VERSION "MFE24 Sensor Master v3 (ascii-safe)"

NS_ :

BS_:

BU_: FrontNode RearCAN RideHeight VehicleController AccelNode

BO_ 800 BrakeRotorTemps: 8 FrontNode
 SG_ BrakeTemp_FL : 0|16@1+ (0.1,0) [0|150] "degC" Vector__XXX
 SG_ BrakeTemp_FR : 16|16@1+ (0.1,0) [0|150] "degC" Vector__XXX

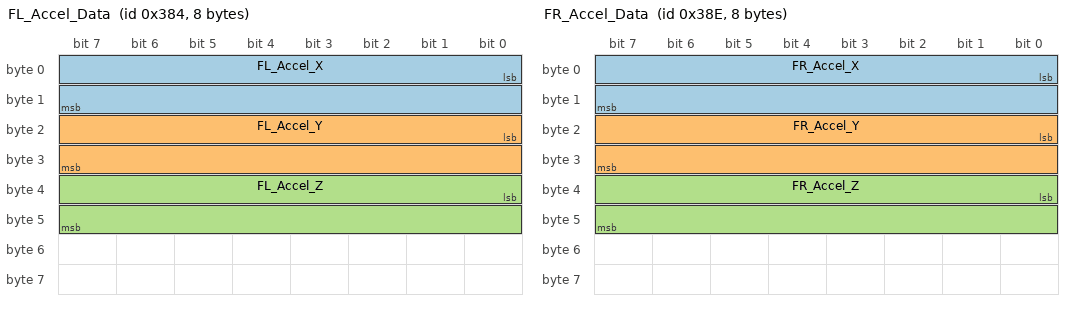
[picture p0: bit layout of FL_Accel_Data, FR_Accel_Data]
BO_ 900 FL_Accel_Data: 8 AccelNode
 SG_ FL_Accel_X : 0|16@1- (0.000244140625,0) [-524288|524287.999755859] "g" Vector__XXX
 SG_ FL_Accel_Y : 16|16@1- (0.000244140625,0) [-8|8] "g" Vector__XXX
 SG_ FL_Accel_Z : 32|16@1- (0.000244140625,0) [-8|8] "g" Vector__XXX

BO_ 910 FR_Accel_Data: 8 AccelNode
 SG_ FR_Accel_X : 0|16@1- (0.000244140625,0) [-8|8] "g" Vector__XXX
 SG_ FR_Accel_Y : 16|16@1- (0.000244140625,0) [-8|8] "g" Vector__XXX
 SG_ FR_Accel_Z : 32|16@1- (0.000244140625,0) [-8|8] "g" Vector__XXX

BO_ 700 OilTemps: 8 FrontNode
 SG_ OilTemp_Engine : 0|12@1+ (0.1,-40) [-40|170] "degC" Vector__XXX
 SG_ OilTemp_Gearbox : 12|12@1+ (0.1,-40) [-40|170] "degC" Vector__XXX

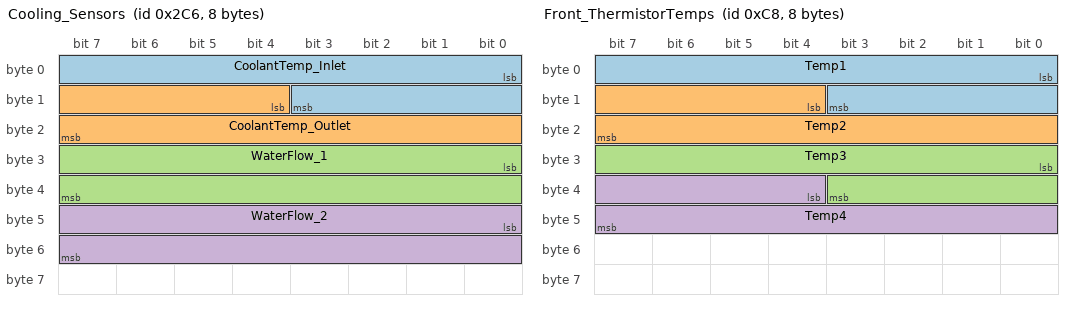
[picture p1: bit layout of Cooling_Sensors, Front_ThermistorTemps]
BO_ 710 Cooling_Sensors: 8 VehicleController
 SG_ CoolantTemp_Inlet : 0|12@1+ (0.1,-40) [-40|180] "degC" Vector__XXX
 SG_ CoolantTemp_Outlet : 12|12@1+ (0.1,-40) [-40|180] "degC" Vector__XXX
 SG_ WaterFlow_1 : 24|16@1+ (0.01,0) [0|25] "L/min" Vector__XXX
 SG_ WaterFlow_2 : 40|16@1+ (0.01,0) [0|25] "L/min" Vector__XXX

BO_ 100 FUTEK1_Load: 8 FrontNode
 SG_ Load1 : 0|16@1+ (0.1,0) [0|10000] "N" Vector__XXX

BO_ 110 FUTEK2_Load: 8 FrontNode
 SG_ Load2 : 0|16@1+ (0.1,0) [0|10000] "N" Vector__XXX

BO_ 200 Front_ThermistorTemps: 8 FrontNode
 SG_ Temp1 : 0|12@1+ (0.1,-40) [-40|180] "degC" Vector__XXX
 SG_ Temp2 : 12|12@1+ (0.1,-40) [-40|180] "degC" Vector__XXX
 SG_ Temp3 : 24|12@1+ (0.1,-40) [-40|180] "degC" Vector__XXX
 SG_ Temp4 : 36|12@1+ (0.1,-40) [-40|180] "degC" Vector__XXX

BO_ 300 Front_RotPotAngles: 8 FrontNode
 SG_ Angle1 : 0|16@1+ (0.01,0) [0|90] "deg" Vector__XXX
 SG_ Angle2 : 16|16@1+ (0.01,0) [0|90] "deg" Vector__XXX

BO_ 210 BrakeLineTemp_Front: 8 FrontNode
 SG_ BrakeLineTemp_Front : 0|16@1+ (0.1,-40) [-40|500] "degC" Vector__XXX

BO_ 400 Rear_LoadCells: 8 RearCAN
 SG_ Load1 : 0|16@1+ (0.1,0) [0|10000] "N" Vector__XXX
 SG_ Load2 : 16|16@1+ (0.1,0) [0|10000] "N" Vector__XXX

BO_ 500 Rear_RotPotAngles: 8 RearCAN
 SG_ Angle1 : 0|16@1+ (0.01,0) [0|90] "deg" Vector__XXX
 SG_ Angle2 : 16|16@1+ (0.01,0) [0|90] "deg" Vector__XXX

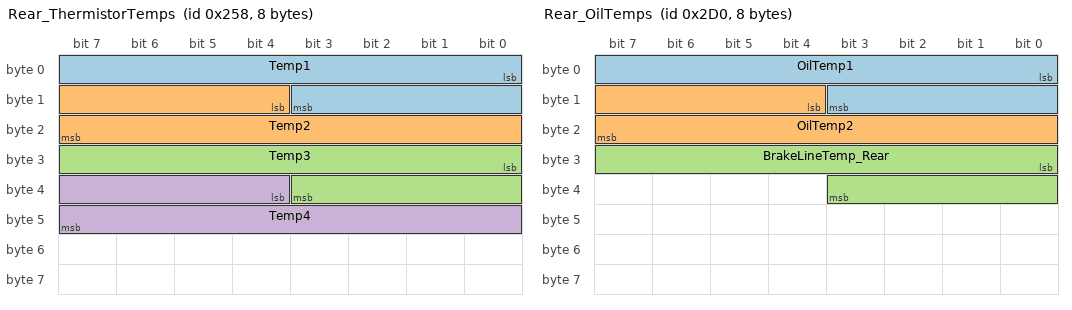
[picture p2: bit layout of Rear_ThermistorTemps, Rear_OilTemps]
BO_ 600 Rear_ThermistorTemps: 8 RearCAN
 SG_ Temp1 : 0|12@1+ (0.1,-40) [-40|180] "degC" Vector__XXX
 SG_ Temp2 : 12|12@1+ (0.1,-40) [-40|180] "degC" Vector__XXX
 SG_ Temp3 : 24|12@1+ (0.1,-40) [-40|180] "degC" Vector__XXX
 SG_ Temp4 : 36|12@1+ (0.1,-40) [-40|180] "degC" Vector__XXX

BO_ 720 Rear_OilTemps: 8 RearCAN
 SG_ OilTemp1 : 0|12@1+ (0.1,-40) [-40|170] "degC" Vector__XXX
 SG_ OilTemp2 : 12|12@1+ (0.1,-40) [-40|170] "degC" Vector__XXX
 SG_ BrakeLineTemp_Rear : 24|12@1+ (0.1,-40) [-40|500] "degC" Vector__XXX

BO_ 810 Rear_BrakeRotorTemp: 8 RearCAN
 SG_ BrakeTemp : 0|16@1+ (0.1,0) [0|150] "degC" Vector__XXX

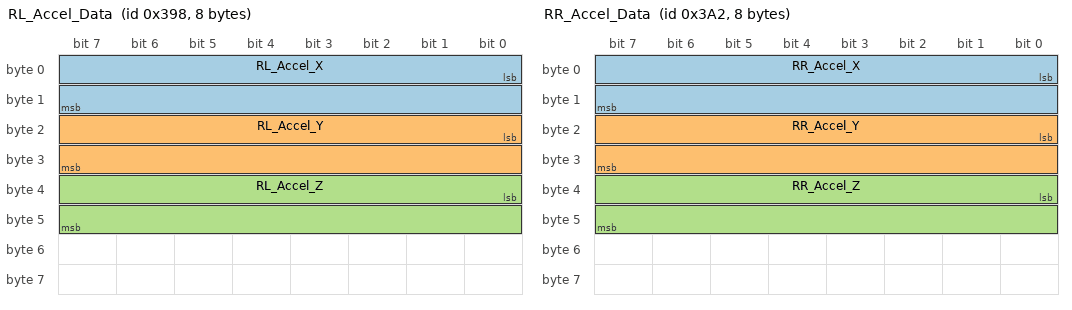
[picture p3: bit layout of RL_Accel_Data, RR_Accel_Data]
BO_ 920 RL_Accel_Data: 8 AccelNode
 SG_ RL_Accel_X : 0|16@1- (0.000244140625,0) [-8|8] "g" Vector__XXX
 SG_ RL_Accel_Y : 16|16@1- (0.000244140625,0) [-8|8] "g" Vector__XXX
 SG_ RL_Accel_Z : 32|16@1- (0.000244140625,0) [-8|7.999755859375] "g" Vector__XXX

BO_ 930 RR_Accel_Data: 8 AccelNode
 SG_ RR_Accel_X : 0|16@1- (0.000244140625,0) [-8|8] "g" Vector__XXX
 SG_ RR_Accel_Y : 16|16@1- (0.000244140625,0) [-8|8] "g" Vector__XXX
 SG_ RR_Accel_Z : 32|16@1- (0.000244140625,0) [-8|8] "g" Vector__XXX

BO_ 610 RideHeight_Front_Data: 2 RideHeight
 SG_ RideHeight_Front : 0|16@1+ (1,0) [0|500] "mm" Vector__XXX

BO_ 611 RideHeight_RL_Data: 2 RideHeight
 SG_ RideHeight_RL : 0|16@1+ (1,0) [0|500] "mm" Vector__XXX

BO_ 612 RideHeight_RR_Data: 2 RideHeight
 SG_ RideHeight_RR : 0|16@1+ (1,0) [0|500] "mm" Vector__XXX

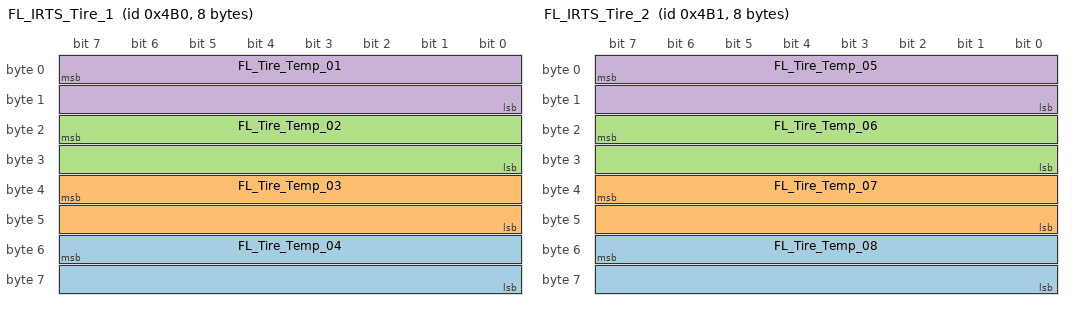
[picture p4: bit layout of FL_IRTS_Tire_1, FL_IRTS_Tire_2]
BO_ 1200 FL_IRTS_Tire_1: 8 Vector__XXX
 SG_ FL_Tire_Temp_04 : 55|16@0+ (0.1,-100) [-100|6453.5] "degC" Vector__XXX
 SG_ FL_Tire_Temp_03 : 39|16@0+ (0.1,-100) [-100|6453.5] "degC" Vector__XXX
 SG_ FL_Tire_Temp_02 : 23|16@0+ (0.1,-100) [-100|6453.5] "degC" Vector__XXX
 SG_ FL_Tire_Temp_01 : 7|16@0+ (0.1,-100) [-100|6453.5] "degC" Vector__XXX

BO_ 1201 FL_IRTS_Tire_2: 8 Vector__XXX
 SG_ FL_Tire_Temp_08 : 55|16@0+ (0.1,-100) [-100|6453.5] "degC" Vector__XXX
 SG_ FL_Tire_Temp_07 : 39|16@0+ (0.1,-100) [-100|6453.5] "degC" Vector__XXX
 SG_ FL_Tire_Temp_06 : 23|16@0+ (0.1,-100) [-100|6453.5] "degC" Vector__XXX
 SG_ FL_Tire_Temp_05 : 7|16@0+ (0.1,-100) [-100|6453.5] "degC" Vector__XXX

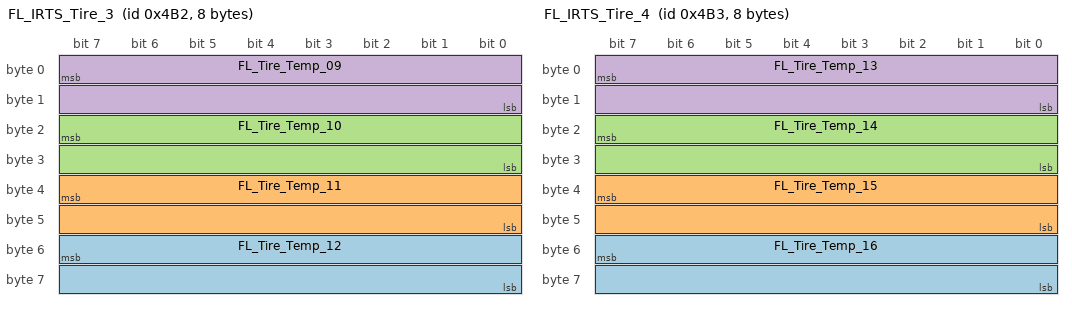
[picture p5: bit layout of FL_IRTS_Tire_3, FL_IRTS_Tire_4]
BO_ 1202 FL_IRTS_Tire_3: 8 Vector__XXX
 SG_ FL_Tire_Temp_12 : 55|16@0+ (0.1,-100) [-100|6453.5] "degC" Vector__XXX
 SG_ FL_Tire_Temp_11 : 39|16@0+ (0.1,-100) [-100|6453.5] "degC" Vector__XXX
 SG_ FL_Tire_Temp_10 : 23|16@0+ (0.1,-100) [-100|6453.5] "degC" Vector__XXX
 SG_ FL_Tire_Temp_09 : 7|16@0+ (0.1,-100) [-100|6453.5] "degC" Vector__XXX

BO_ 1203 FL_IRTS_Tire_4: 8 Vector__XXX
 SG_ FL_Tire_Temp_16 : 55|16@0+ (0.1,-100) [-100|6453.5] "degC" Vector__XXX
 SG_ FL_Tire_Temp_15 : 39|16@0+ (0.1,-100) [-100|6453.5] "degC" Vector__XXX
 SG_ FL_Tire_Temp_14 : 23|16@0+ (0.1,-100) [-100|6453.5] "degC" Vector__XXX
 SG_ FL_Tire_Temp_13 : 7|16@0+ (0.1,-100) [-100|6453.5] "degC" Vector__XXX

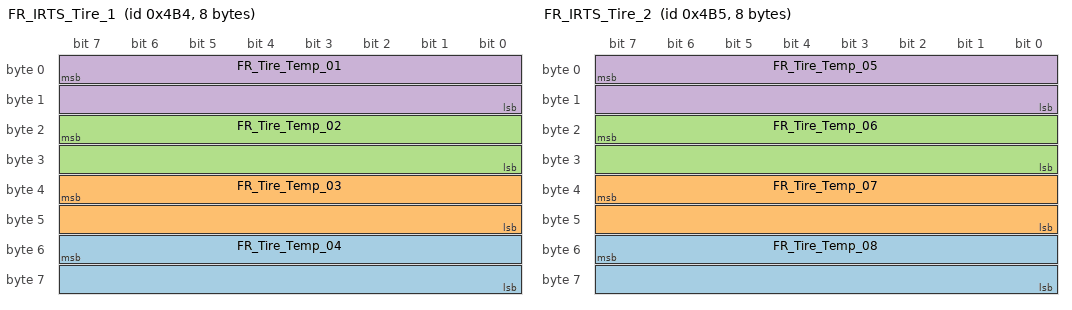
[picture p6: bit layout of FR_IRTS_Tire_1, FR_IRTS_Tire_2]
BO_ 1204 FR_IRTS_Tire_1: 8 Vector__XXX
 SG_ FR_Tire_Temp_04 : 55|16@0+ (0.1,-100) [-100|6453.5] "degC" Vector__XXX
 SG_ FR_Tire_Temp_03 : 39|16@0+ (0.1,-100) [-100|6453.5] "degC" Vector__XXX
 SG_ FR_Tire_Temp_02 : 23|16@0+ (0.1,-100) [-100|6453.5] "degC" Vector__XXX
 SG_ FR_Tire_Temp_01 : 7|16@0+ (0.1,-100) [-100|6453.5] "degC" Vector__XXX

BO_ 1205 FR_IRTS_Tire_2: 8 Vector__XXX
 SG_ FR_Tire_Temp_08 : 55|16@0+ (0.1,-100) [-100|6453.5] "degC" Vector__XXX
 SG_ FR_Tire_Temp_07 : 39|16@0+ (0.1,-100) [-100|6453.5] "degC" Vector__XXX
 SG_ FR_Tire_Temp_06 : 23|16@0+ (0.1,-100) [-100|6453.5] "degC" Vector__XXX
 SG_ FR_Tire_Temp_05 : 7|16@0+ (0.1,-100) [-100|6453.5] "degC" Vector__XXX

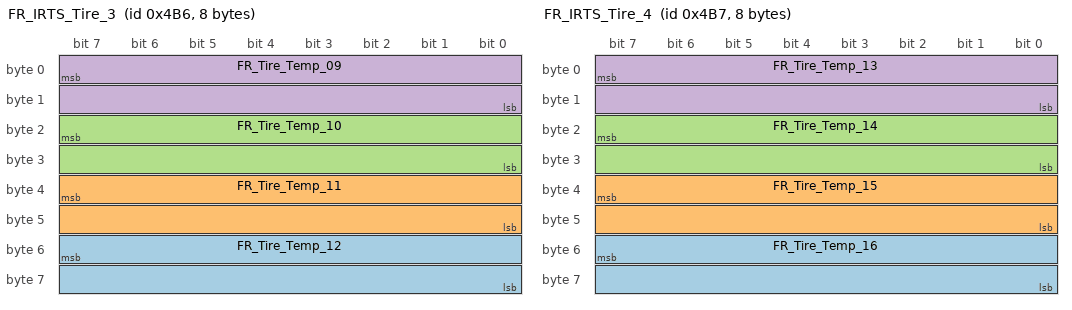
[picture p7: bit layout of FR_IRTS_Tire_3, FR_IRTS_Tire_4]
BO_ 1206 FR_IRTS_Tire_3: 8 Vector__XXX
 SG_ FR_Tire_Temp_12 : 55|16@0+ (0.1,-100) [-100|6453.5] "degC" Vector__XXX
 SG_ FR_Tire_Temp_11 : 39|16@0+ (0.1,-100) [-100|6453.5] "degC" Vector__XXX
 SG_ FR_Tire_Temp_10 : 23|16@0+ (0.1,-100) [-100|6453.5] "degC" Vector__XXX
 SG_ FR_Tire_Temp_09 : 7|16@0+ (0.1,-100) [-100|6453.5] "degC" Vector__XXX

BO_ 1207 FR_IRTS_Tire_4: 8 Vector__XXX
 SG_ FR_Tire_Temp_16 : 55|16@0+ (0.1,-100) [-100|6453.5] "degC" Vector__XXX
 SG_ FR_Tire_Temp_15 : 39|16@0+ (0.1,-100) [-100|6453.5] "degC" Vector__XXX
 SG_ FR_Tire_Temp_14 : 23|16@0+ (0.1,-100) [-100|6453.5] "degC" Vector__XXX
 SG_ FR_Tire_Temp_13 : 7|16@0+ (0.1,-100) [-100|6453.5] "degC" Vector__XXX

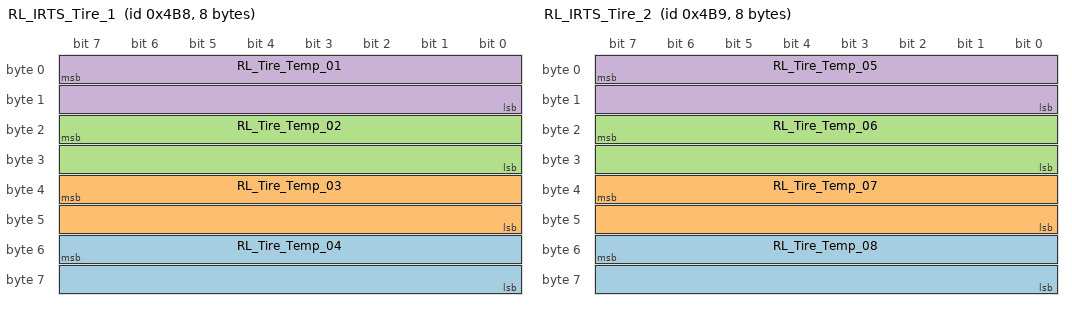
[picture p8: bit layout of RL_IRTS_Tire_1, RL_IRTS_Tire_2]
BO_ 1208 RL_IRTS_Tire_1: 8 Vector__XXX
 SG_ RL_Tire_Temp_04 : 55|16@0+ (0.1,-100) [-100|6453.5] "degC" Vector__XXX
 SG_ RL_Tire_Temp_03 : 39|16@0+ (0.1,-100) [-100|6453.5] "degC" Vector__XXX
 SG_ RL_Tire_Temp_02 : 23|16@0+ (0.1,-100) [-100|6453.5] "degC" Vector__XXX
 SG_ RL_Tire_Temp_01 : 7|16@0+ (0.1,-100) [-100|6453.5] "degC" Vector__XXX

BO_ 1209 RL_IRTS_Tire_2: 8 Vector__XXX
 SG_ RL_Tire_Temp_08 : 55|16@0+ (0.1,-100) [-100|6453.5] "degC" Vector__XXX
 SG_ RL_Tire_Temp_07 : 39|16@0+ (0.1,-100) [-100|6453.5] "degC" Vector__XXX
 SG_ RL_Tire_Temp_06 : 23|16@0+ (0.1,-100) [-100|6453.5] "degC" Vector__XXX
 SG_ RL_Tire_Temp_05 : 7|16@0+ (0.1,-100) [-100|6453.5] "degC" Vector__XXX

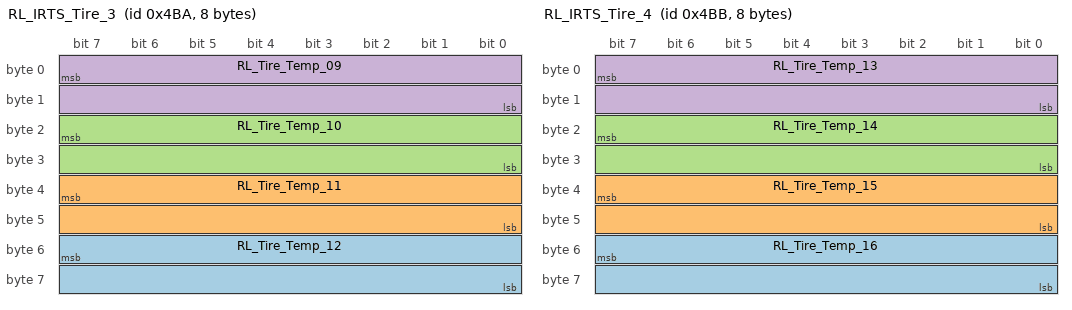
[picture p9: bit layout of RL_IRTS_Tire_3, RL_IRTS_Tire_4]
BO_ 1210 RL_IRTS_Tire_3: 8 Vector__XXX
 SG_ RL_Tire_Temp_12 : 55|16@0+ (0.1,-100) [-100|6453.5] "degC" Vector__XXX
 SG_ RL_Tire_Temp_11 : 39|16@0+ (0.1,-100) [-100|6453.5] "degC" Vector__XXX
 SG_ RL_Tire_Temp_10 : 23|16@0+ (0.1,-100) [-100|6453.5] "degC" Vector__XXX
 SG_ RL_Tire_Temp_09 : 7|16@0+ (0.1,-100) [-100|6453.5] "degC" Vector__XXX

BO_ 1211 RL_IRTS_Tire_4: 8 Vector__XXX
 SG_ RL_Tire_Temp_16 : 55|16@0+ (0.1,-100) [-100|6453.5] "degC" Vector__XXX
 SG_ RL_Tire_Temp_15 : 39|16@0+ (0.1,-100) [-100|6453.5] "degC" Vector__XXX
 SG_ RL_Tire_Temp_14 : 23|16@0+ (0.1,-100) [-100|6453.5] "degC" Vector__XXX
 SG_ RL_Tire_Temp_13 : 7|16@0+ (0.1,-100) [-100|6453.5] "degC" Vector__XXX

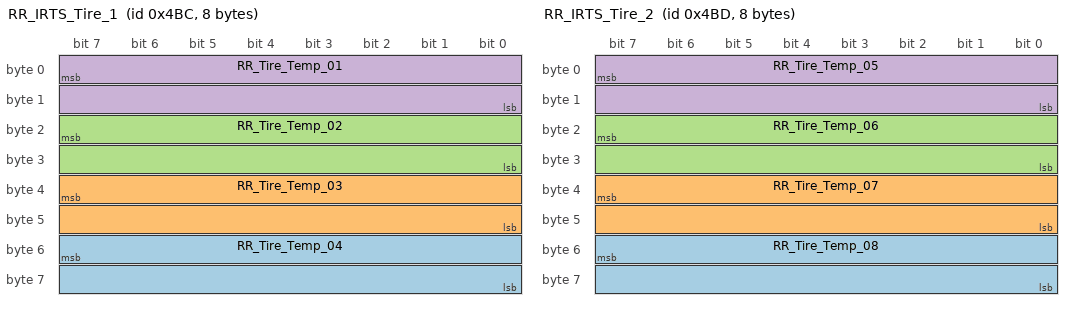
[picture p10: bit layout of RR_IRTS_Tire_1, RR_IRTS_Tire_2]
BO_ 1212 RR_IRTS_Tire_1: 8 Vector__XXX
 SG_ RR_Tire_Temp_04 : 55|16@0+ (0.1,-100) [-100|6453.5] "degC" Vector__XXX
 SG_ RR_Tire_Temp_03 : 39|16@0+ (0.1,-100) [-100|6453.5] "degC" Vector__XXX
 SG_ RR_Tire_Temp_02 : 23|16@0+ (0.1,-100) [-100|6453.5] "degC" Vector__XXX
 SG_ RR_Tire_Temp_01 : 7|16@0+ (0.1,-100) [-100|6453.5] "degC" Vector__XXX

BO_ 1213 RR_IRTS_Tire_2: 8 Vector__XXX
 SG_ RR_Tire_Temp_08 : 55|16@0+ (0.1,-100) [-100|6453.5] "degC" Vector__XXX
 SG_ RR_Tire_Temp_07 : 39|16@0+ (0.1,-100) [-100|6453.5] "degC" Vector__XXX
 SG_ RR_Tire_Temp_06 : 23|16@0+ (0.1,-100) [-100|6453.5] "degC" Vector__XXX
 SG_ RR_Tire_Temp_05 : 7|16@0+ (0.1,-100) [-100|6453.5] "degC" Vector__XXX

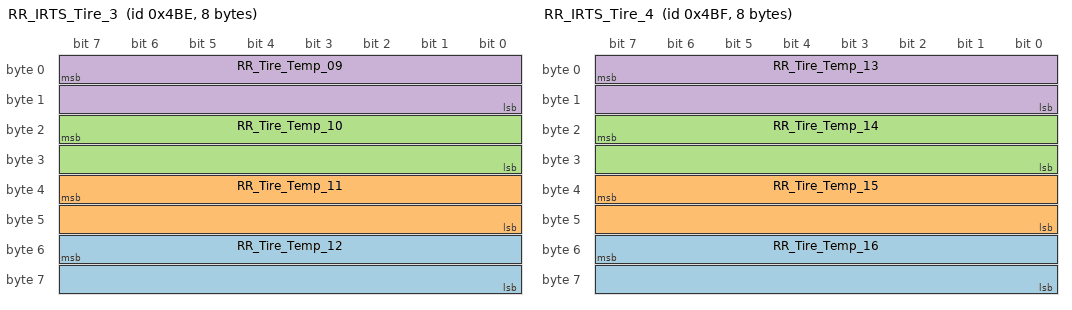
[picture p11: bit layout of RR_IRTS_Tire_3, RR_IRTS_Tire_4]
BO_ 1214 RR_IRTS_Tire_3: 8 Vector__XXX
 SG_ RR_Tire_Temp_12 : 55|16@0+ (0.1,-100) [-100|6453.5] "degC" Vector__XXX
 SG_ RR_Tire_Temp_11 : 39|16@0+ (0.1,-100) [-100|6453.5] "degC" Vector__XXX
 SG_ RR_Tire_Temp_10 : 23|16@0+ (0.1,-100) [-100|6453.5] "degC" Vector__XXX
 SG_ RR_Tire_Temp_09 : 7|16@0+ (0.1,-100) [-100|6453.5] "degC" Vector__XXX

BO_ 1215 RR_IRTS_Tire_4: 8 Vector__XXX
 SG_ RR_Tire_Temp_16 : 55|16@0+ (0.1,-100) [-100|6453.5] "degC" Vector__XXX
 SG_ RR_Tire_Temp_15 : 39|16@0+ (0.1,-100) [-100|6453.5] "degC" Vector__XXX
 SG_ RR_Tire_Temp_14 : 23|16@0+ (0.1,-100) [-100|6453.5] "degC" Vector__XXX
 SG_ RR_Tire_Temp_13 : 7|16@0+ (0.1,-100) [-100|6453.5] "degC" Vector__XXX
